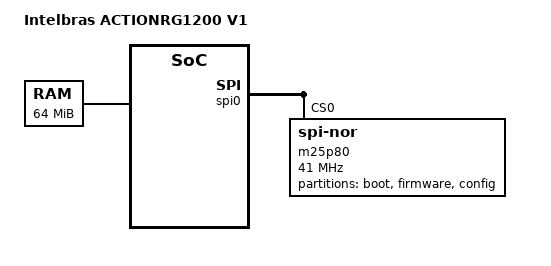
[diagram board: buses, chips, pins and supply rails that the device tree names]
// SPDX-License-Identifier: GPL-2.0
/dts-v1/;

#include "RTL8197F.dtsi"

/ {
	compatible = "intelbras,actionrg1200", "realtek,rtl8197f-soc";
	model = "Intelbras ACTIONRG1200 V1";

	memory {
		device_type = "memory";
		reg = <0x0 0x4000000>;
	};

	chosen {
		bootargs = "console=ttyS0,115200";
	};
};

&spi0 {
	status = "okay";

	m25p80@0 {
		#address-cells = <1>;
		#size-cells = <1>;
		compatible = "jedec,spi-nor";
		reg = <0>;
		spi-max-frequency = <41000000>;

		partition@0 {
			label = "boot";
			reg = <0x0 0x30000>;
			read-only;
		};

		partition@30000 {
			label = "firmware";
			reg = <0x30000 0x7B0000>;
		};

		partition@7E0000 {
			label = "config";
			reg = <0x7E0000 0x10000>;
			read-only;
		};
	};
};
